# TM4C1294NCPDT register map
Vendor: Texas Instruments; File version: 2.2.0.295
CPU: CM4 r0p1, little endian, MPU, FPU, 3 interrupt priority bits
Registers are 32-bit, read-write, no defined reset value unless marked. A register's access mark holds for its fields unless they carry their own. Offsets are from the block's base; [hi:lo] are bit positions; {n}, {i} and the like mark numbered series.

## USB0 — Univeral Serial Bus (USB0)
Base 0x40050000
{0x20+4i} FIFO{i} read-modifies (i=0..7)
  [31:0] EPDATA — Endpoint Data
{0x208+0x10*i} DMAADDR{i} (i=0..7)
  [31:2] ADDR — DMA Address
{0x20C+0x10*i} DMACOUNT{i} (i=0..7)
  [31:2] COUNT — DMA Count
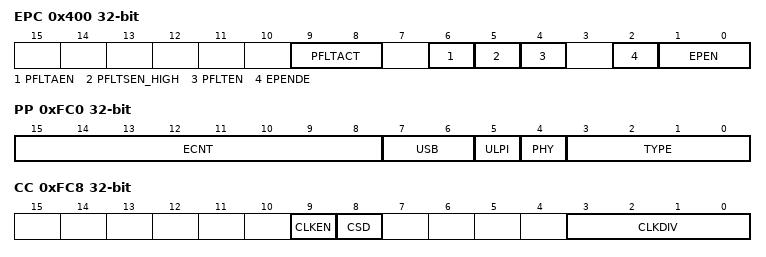
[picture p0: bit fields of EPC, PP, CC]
0x400 EPC
  [9:8] PFLTACT — Power Fault Action
    0=UNCHG (Unchanged); 1=TRIS (Tristate); 2=LOW; 3=HIGH
  [6] PFLTAEN — Power Fault Action Enable
  [5] PFLTSEN_HIGH — Power Fault Sense
  [4] PFLTEN — Power Fault Input Enable
  [2] EPENDE — EPEN Drive Enable
  [1:0] EPEN — External Power Supply Enable
    0=LOW (Power Enable Active Low); 1=HIGH (Power Enable Active High); 2=VBLOW (Power Enable High if VBUS Low); 3=VBHIGH (Power Enable High if VBUS High)
0x404 EPCRIS
  [0] PF — USB Power Fault Interrupt Status
0x408 EPCIM
  [0] PF — USB Power Fault Interrupt Mask
0x40C EPCISC
  [0] PF — USB Power Fault Interrupt Status
0x410 DRRIS
  [0] RESUME — RESUME Interrupt Status
0x414 DRIM
  [0] RESUME — RESUME Interrupt Mask
0x418 DRISC
  [0] RESUME — RESUME Interrupt Status and
0x41C GPCS
  [2:0] DEVMOD — Device Mode
    0=OTG (Use USB0VBUS and USB0ID pin); 2=HOST (Force USB0VBUS and USB0ID low); 3=DEV (Force USB0VBUS and USB0ID high); 4=HOSTVBUS (Use USB0VBUS and force USB0ID); 5=DEVVBUS (Use USB0VBUS and force USB0ID)
0x430 VDC
  [0] VBDEN — VBUS Droop Enable
0x434 VDCRIS
  [0] VD — VBUS Droop Raw Interrupt Status
0x438 VDCIM
  [0] VD — VBUS Droop Interrupt Mask
0x43C VDCISC
  [0] VD — VBUS Droop Interrupt Status and
0xFC0 PP
  [15:8] ECNT — Endpoint Count
  [7:6] USB — USB Capability
    1=DEVICE; 2=HOSTDEVICE; 3=OTG
  [5] ULPI — ULPI Present
  [4] PHY — PHY Present
  [3:0] TYPE — Controller Type
    0=The first-generation USB; 1=Second-generation USB
0xFC4 PC
  [16] ULPIEN — ULPI Enable
0xFC8 CC
  [9] CLKEN — USB Clock Enable
  [8] CSD — Clock Source/Direction
  [3:0] CLKDIV — PLL Clock Divisor

## GPIO_PORTA_AHB
Base 0x40058000
Same registers: GPIO_PORTB_AHB 0x40059000, GPIO_PORTC_AHB 0x4005A000, GPIO_PORTD_AHB 0x4005B000, GPIO_PORTE_AHB 0x4005C000, GPIO_PORTF_AHB 0x4005D000, GPIO_PORTG_AHB 0x4005E000, GPIO_PORTH_AHB 0x4005F000, GPIO_PORTJ_AHB 0x40060000, GPIO_PORTK 0x40061000, GPIO_PORTL 0x40062000, GPIO_PORTM 0x40063000, GPIO_PORTN 0x40064000, GPIO_PORTP 0x40065000, GPIO_PORTQ 0x40066000
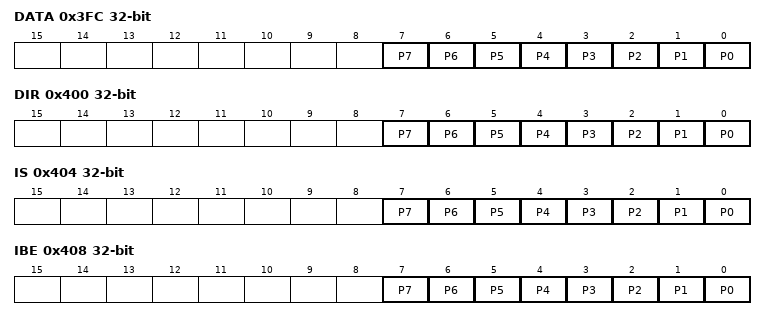
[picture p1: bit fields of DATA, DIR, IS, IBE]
0x3FC DATA
  [n] P{n} (n=0..7) — Pin {n}
0x400 DIR
  [n] P{n} (n=0..7) — Pin {n}
0x404 IS
  [n] P{n} (n=0..7) — Pin {n}
0x408 IBE
  [n] P{n} (n=0..7) — Pin {n}
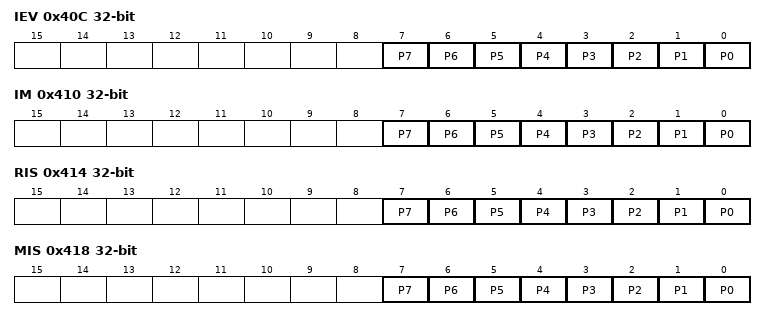
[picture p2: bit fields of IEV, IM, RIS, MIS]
0x40C IEV
  [n] P{n} (n=0..7) — Pin {n}
0x410 IM
  [n] P{n} (n=0..7) — Pin {n}
0x414 RIS
  [n] P{n} (n=0..7) — Pin {n}
0x418 MIS
  [n] P{n} (n=0..7) — Pin {n}
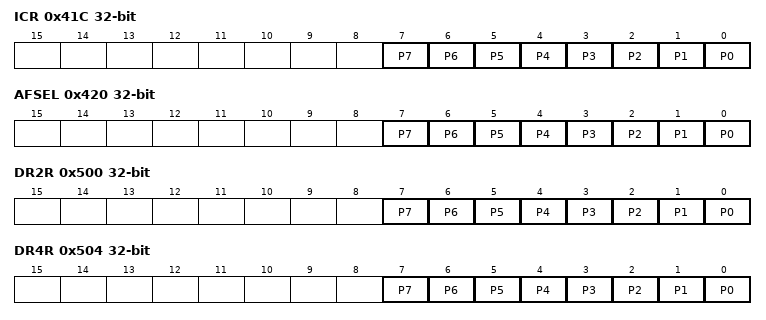
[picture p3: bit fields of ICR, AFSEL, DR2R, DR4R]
0x41C ICR
  [n] P{n} (n=0..7) — Pin {n}
0x420 AFSEL
  [n] P{n} (n=0..7) — Pin {n}
0x500 DR2R
  [n] P{n} (n=0..7) — Pin {n}
0x504 DR4R
  [n] P{n} (n=0..7) — Pin {n}
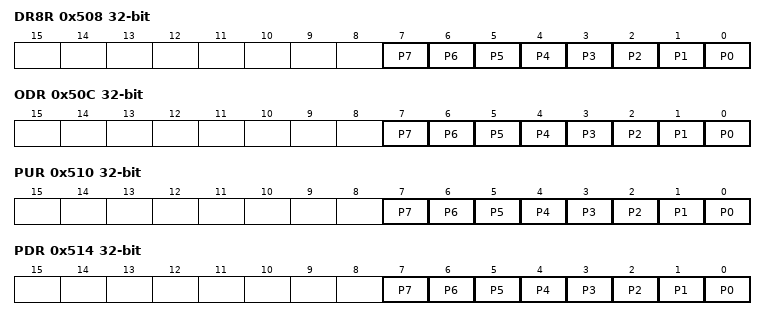
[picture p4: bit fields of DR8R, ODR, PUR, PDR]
0x508 DR8R
  [n] P{n} (n=0..7) — Pin {n}
0x50C ODR
  [n] P{n} (n=0..7) — Pin {n}
0x510 PUR
  [n] P{n} (n=0..7) — Pin {n}
0x514 PDR
  [n] P{n} (n=0..7) — Pin {n}
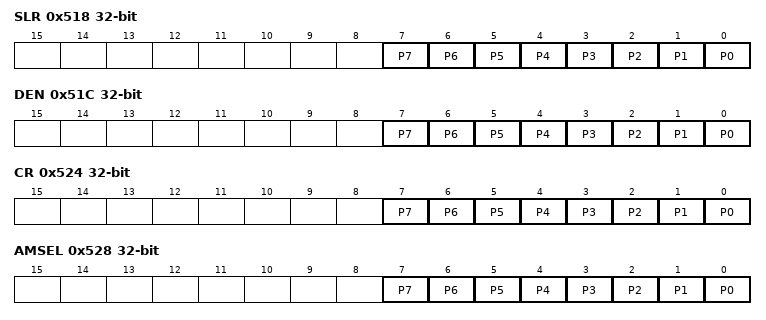
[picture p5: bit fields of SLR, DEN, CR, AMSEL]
0x518 SLR
  [n] P{n} (n=0..7) — Pin {n}
0x51C DEN
  [n] P{n} (n=0..7) — Pin {n}
0x520 LOCK
0x524 CR
  [n] P{n} (n=0..7) — Pin {n}
0x528 AMSEL
  [n] P{n} (n=0..7) — Pin {n}
0x52C PCTL
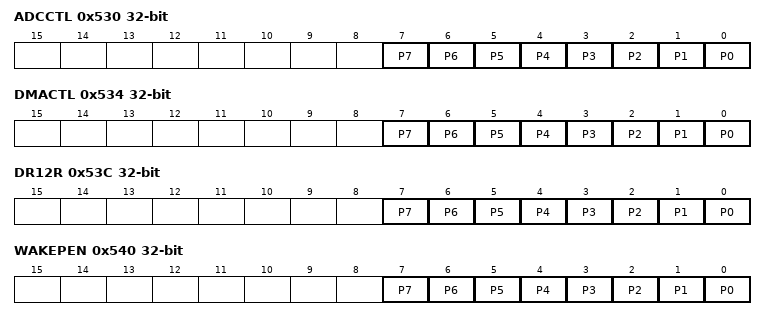
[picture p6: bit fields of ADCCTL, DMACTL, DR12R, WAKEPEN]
0x530 ADCCTL
  [n] P{n} (n=0..7) — Pin {n}
0x534 DMACTL
  [n] P{n} (n=0..7) — Pin {n}
0x538 SI
0x53C DR12R
  [n] P{n} (n=0..7) — Pin {n}
0x540 WAKEPEN
  [n] P{n} (n=0..7) — Pin {n}
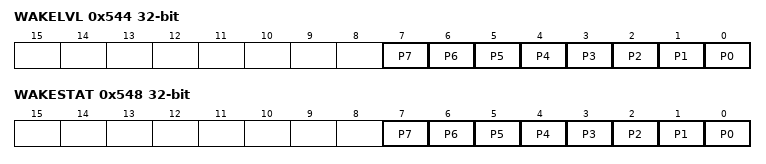
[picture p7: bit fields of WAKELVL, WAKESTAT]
0x544 WAKELVL
  [n] P{n} (n=0..7) — Pin {n}
0x548 WAKESTAT
  [n] P{n} (n=0..7) — Pin {n}
0xFC0 PP
0xFC4 PC

## EEPROM — EEPROM (EEPROM)
Base 0x400AF000
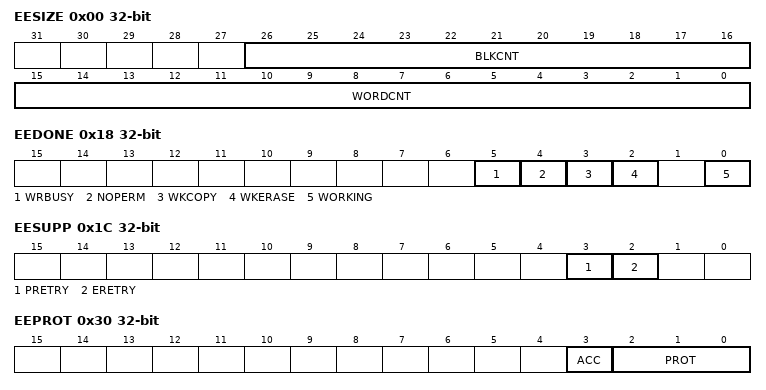
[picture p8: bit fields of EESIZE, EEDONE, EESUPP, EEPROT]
0x00 EESIZE
  [26:16] BLKCNT — Number of 16-Word Blocks
  [15:0] WORDCNT — Number of 32-Bit Words
0x04 EEBLOCK
  [15:0] BLOCK — Current Block
0x08 EEOFFSET
  [3:0] OFFSET — Current Address Offset
0x10 EERDWR
  [31:0] VALUE — EEPROM Read or Write Data
0x14 EERDWRINC
  [31:0] VALUE — EEPROM Read or Write Data with
0x18 EEDONE
  [5] WRBUSY — Write Busy
  [4] NOPERM — Write Without Permission
  [3] WKCOPY — Working on a Copy
  [2] WKERASE — Working on an Erase
  [0] WORKING — EEPROM Working
0x1C EESUPP
  [3] PRETRY — Programming Must Be Retried
  [2] ERETRY — Erase Must Be Retried
0x20 EEUNLOCK
  [31:0] UNLOCK — EEPROM Unlock
0x30 EEPROT
  [3] ACC — Access Control
  [2:0] PROT — Protection Control
    0=RWNPW (This setting is the default. If); 1=RWPW (If there is a password, the); 2=RONPW (If there is no password, the)
{0x34+4i} EEPASS{i} (i=0..2)
  [31:0] PASS — Password
0x40 EEINT
  [0] INT — Interrupt Enable
0x50 EEHIDE0
  [31:1] HN — Hide Block
0x54 EEHIDE1
  [31:0] HN — Hide Block
0x58 EEHIDE2
  [31:0] HN — Hide Block
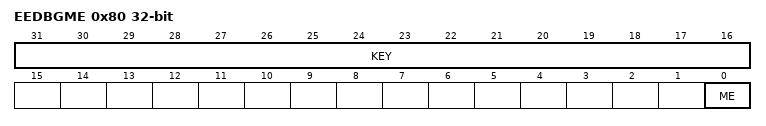
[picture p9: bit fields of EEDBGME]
0x80 EEDBGME
  [31:16] KEY — Erase Key
  [0] ME — Mass Erase
0xFC0 PP
  [15:0] SIZE — EEPROM Size
    0=64 bytes of EEPROM; 1=128 bytes of EEPROM; 3=256 bytes of EEPROM; 7=512 bytes of EEPROM; 15=1K (1 KB of EEPROM); 31=2K (2 KB of EEPROM); 63=3K (3 KB of EEPROM); 127=4K (4 KB of EEPROM); 255=5K (5 KB of EEPROM); 0x1FF=6K (6 KB of EEPROM)
